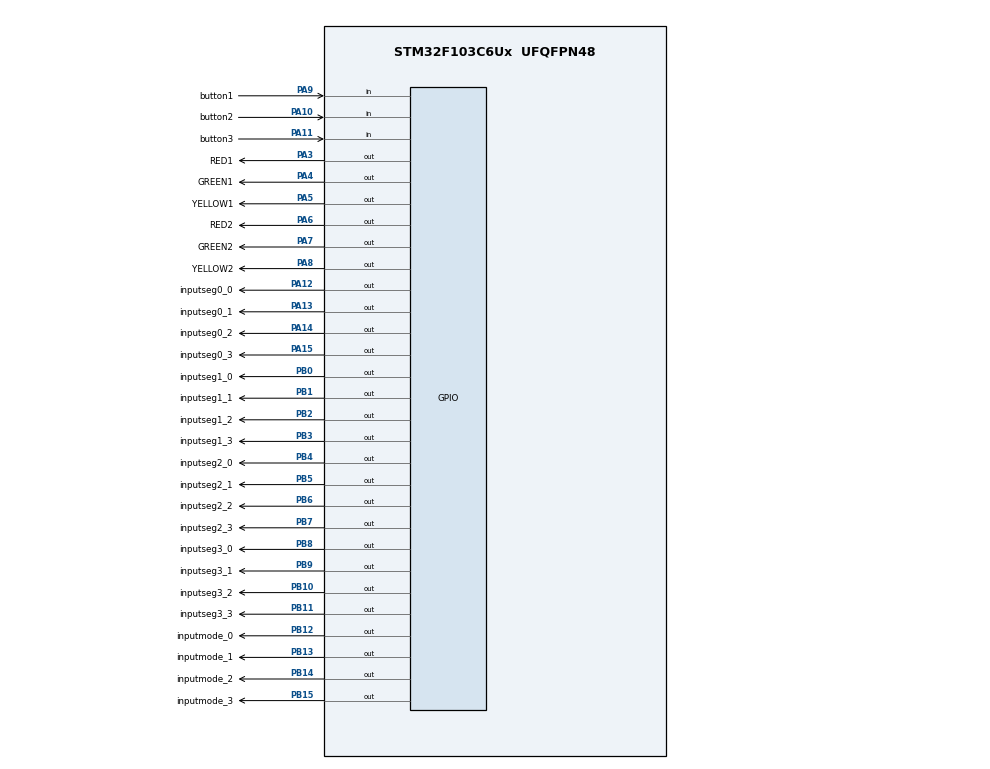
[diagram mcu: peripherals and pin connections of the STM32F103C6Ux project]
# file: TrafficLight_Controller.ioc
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Mcu.Family=STM32F1
Mcu.Name=STM32F103C6Ux
Mcu.Package=UFQFPN48
NVIC.PriorityGroup=NVIC_PRIORITYGROUP_4
NVIC.TIM2_IRQn=true\:0\:0\:false\:false\:true\:true\:true
PA10.GPIO_Label=button2
PA10.GPIO_PuPd=GPIO_PULLUP
PA10.Signal=GPIO_Input
PA11.GPIO_Label=button3
PA11.GPIO_PuPd=GPIO_PULLUP
PA11.Signal=GPIO_Input
PA12.GPIO_Label=inputseg0_0
PA12.GPIO_ModeDefaultOutputPP=GPIO_MODE_OUTPUT_PP
PA12.GPIO_PuPd=GPIO_NOPULL
PA12.Signal=GPIO_Output
PA13.GPIO_Label=inputseg0_1
PA13.GPIO_ModeDefaultOutputPP=GPIO_MODE_OUTPUT_PP
PA13.GPIO_PuPd=GPIO_NOPULL
PA13.Signal=GPIO_Output
PA14.GPIO_Label=inputseg0_2
PA14.Signal=GPIO_Output
PA15.GPIO_Label=inputseg0_3
PA15.Signal=GPIO_Output
PA3.GPIO_Label=RED1
PA3.Signal=GPIO_Output
PA4.GPIO_Label=GREEN1
PA4.Signal=GPIO_Output
PA5.GPIO_Label=YELLOW1
PA5.Signal=GPIO_Output
PA6.GPIO_Label=RED2
PA6.Signal=GPIO_Output
PA7.GPIO_Label=GREEN2
PA7.Signal=GPIO_Output
PA8.GPIO_Label=YELLOW2
PA8.GPIO_PuPd=GPIO_NOPULL
PA8.Signal=GPIO_Output
PA9.GPIO_Label=button1
PA9.GPIO_PuPd=GPIO_PULLUP
PA9.Signal=GPIO_Input
PB0.GPIO_Label=inputseg1_0
PB0.Signal=GPIO_Output
PB1.GPIO_Label=inputseg1_1
PB1.Signal=GPIO_Output
PB10.GPIO_Label=inputseg3_2
PB10.Signal=GPIO_Output
PB11.GPIO_Label=inputseg3_3
PB11.Signal=GPIO_Output
PB12.GPIO_Label=inputmode_0
PB12.Signal=GPIO_Output
PB13.GPIO_Label=inputmode_1
PB13.Signal=GPIO_Output
PB14.GPIO_Label=inputmode_2
PB14.Signal=GPIO_Output
PB15.GPIO_Label=inputmode_3
PB15.Signal=GPIO_Output
PB2.GPIO_Label=inputseg1_2
PB2.Signal=GPIO_Output
PB3.GPIO_Label=inputseg1_3
PB3.Signal=GPIO_Output
PB4.GPIO_Label=inputseg2_0
PB4.Signal=GPIO_Output
PB5.GPIO_Label=inputseg2_1
PB5.Signal=GPIO_Output
PB6.GPIO_Label=inputseg2_2
PB6.Signal=GPIO_Output
PB7.GPIO_Label=inputseg2_3
PB7.Signal=GPIO_Output
PB8.GPIO_Label=inputseg3_0
PB8.Signal=GPIO_Output
PB9.GPIO_Label=inputseg3_1
PB9.Signal=GPIO_Output
ProjectManager.HeapSize=0x200
ProjectManager.StackSize=0x400
ProjectManager.TargetToolchain=STM32CubeIDE
RCC.APB1Freq_Value=8000000
RCC.APB2Freq_Value=8000000
TIM2.Period=9
TIM2.Prescaler=7999
VP_SYS_VS_ND.Mode=No_Debug
VP_TIM2_VS_ClockSourceINT.Mode=Internal
board=custom

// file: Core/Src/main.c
/* USER CODE BEGIN Header */
/**
  ******************************************************************************
  * @file           : main.c
  * @brief          : Traffic Light System - Main Program (FIXED)
  *                   Chương trình chính đi�?u khiển hệ thống đèn giao thông
  ******************************************************************************
  */
/* USER CODE END Header */
#include "main.h"

/* USER CODE BEGIN Includes */
#include "software_timer.h"    // Thư viện timer phần m�?m (đếm th�?i gian)
#include "button.h"            // Thư viện xử lý nút nhấn
#include "fsm_traffic.h"       // Thư viện FSM (Finite State Machine) đi�?u khiển đèn giao thông
/* USER CODE END Includes */

/* USER CODE BEGIN Header */
/**
  ******************************************************************************
  * @file           : main.c
  * @brief          : Traffic Light System - Main Program (FIXED)
  *                   Chương trình chính điều khiển hệ thống đèn giao thông
  ******************************************************************************
  */
/* USER CODE END Header */

#include "main.h"

/* USER CODE BEGIN Includes */
#include "software_timer.h"    // Thư viện timer phần mềm (đếm thời gian)
#include "button.h"            // Thư viện xử lý nút nhấn
#include "fsm_traffic.h"       // Thư viện FSM (Finite State Machine) điều khiển đèn giao thông
/* USER CODE END Includes */

TIM_HandleTypeDef htim2;    // Biến quản lý Timer 2 (phần cứng)

void SystemClock_Config(void);       // Hàm cấu hình xung clock hệ thống
static void MX_GPIO_Init(void);      // Hàm khởi tạo GPIO (các chân input/output)
static void MX_TIM2_Init(void);      // Hàm khởi tạo Timer 2

/**
  * @brief  Timer interrupt callback - Hàm ngắt Timer
  * @param  htim: Timer handle (con trỏ tới timer đang xử lý)
  * @retval None
  *
  * Giải thích:
  * - Hàm này được gọi TỰ ĐỘNG mỗi khi Timer 2 tràn (overflow)
  * - Thời gian gọi phụ thuộc vào cấu hình Timer (thường là 10ms)
  * - Đây là "tim đập" của hệ thống - mọi xử lý theo thời gian đều dựa vào đây
  */
void HAL_TIM_PeriodElapsedCallback(TIM_HandleTypeDef *htim)
{
    // Kiểm tra xem ngắt có phải từ Timer 2 không
    if (htim->Instance == TIM2) {

        // 1. Cập nhật bộ đếm timer phần mềm
        //    - Giảm giá trị các timer đã set
        //    - Kiểm tra timer nào hết thời gian
        timerRun();

        // 2. Đọc trạng thái các nút nhấn
        //    - Quét trạng thái nút (nhấn/thả)
        //    - Xử lý chống dội phím (debounce)
        //    - Phát hiện sự kiện nhấn (pressed/long pressed)
        getKeyInput();

        // 3. Chạy máy trạng thái điều khiển đèn giao thông
        //    - Xử lý logic chuyển đèn đỏ-vàng-xanh
        //    - Cập nhật LED 7 đoạn
        //    - Xử lý các mode (normal, adjust red, adjust yellow, adjust green)
        traffic_run();
    }
}

int main(void)
{

  /* MCU Configuration--------------------------------------------------------*/

  /* Reset of all peripherals, Initializes the Flash interface and the Systick. */
  HAL_Init();

  /* Configure the system clock */
  SystemClock_Config();

  /* Initialize all configured peripherals */
  MX_GPIO_Init();
  MX_TIM2_Init();
  /* USER CODE BEGIN 2 */

  // Khởi tạo hệ thống đèn giao thông
  traffic_init();
  // Bật Timer interrupt
  HAL_TIM_Base_Start_IT(&htim2);

  /* USER CODE END 2 */

  /* Infinite loop */
  while (1)
  {

  }
}

void SystemClock_Config(void)
{
  RCC_OscInitTypeDef RCC_OscInitStruct = {0};
  RCC_ClkInitTypeDef RCC_ClkInitStruct = {0};

  /** Initializes the RCC Oscillators according to the specified parameters
  * in the RCC_OscInitTypeDef structure.
  */
  RCC_OscInitStruct.OscillatorType = RCC_OSCILLATORTYPE_HSI;
  RCC_OscInitStruct.HSIState = RCC_HSI_ON;
  RCC_OscInitStruct.HSICalibrationValue = RCC_HSICALIBRATION_DEFAULT;
  RCC_OscInitStruct.PLL.PLLState = RCC_PLL_NONE;
  if (HAL_RCC_OscConfig(&RCC_OscInitStruct) != HAL_OK)
  {
    Error_Handler();
  }
  /** Initializes the CPU, AHB and APB buses clocks
  */
  RCC_ClkInitStruct.ClockType = RCC_CLOCKTYPE_HCLK|RCC_CLOCKTYPE_SYSCLK
                              |RCC_CLOCKTYPE_PCLK1|RCC_CLOCKTYPE_PCLK2;
  RCC_ClkInitStruct.SYSCLKSource = RCC_SYSCLKSOURCE_HSI;
  RCC_ClkInitStruct.AHBCLKDivider = RCC_SYSCLK_DIV1;
  RCC_ClkInitStruct.APB1CLKDivider = RCC_HCLK_DIV1;
  RCC_ClkInitStruct.APB2CLKDivider = RCC_HCLK_DIV1;

  if (HAL_RCC_ClockConfig(&RCC_ClkInitStruct, FLASH_LATENCY_0) != HAL_OK)
  {
    Error_Handler();
  }
}

static void MX_TIM2_Init(void)
{

  TIM_ClockConfigTypeDef sClockSourceConfig = {0};
  TIM_MasterConfigTypeDef sMasterConfig = {0};

  htim2.Instance = TIM2;
  htim2.Init.Prescaler = 7999;
  htim2.Init.CounterMode = TIM_COUNTERMODE_UP;
  htim2.Init.Period = 9;
  htim2.Init.ClockDivision = TIM_CLOCKDIVISION_DIV1;
  htim2.Init.AutoReloadPreload = TIM_AUTORELOAD_PRELOAD_DISABLE;
  if (HAL_TIM_Base_Init(&htim2) != HAL_OK)
  {
    Error_Handler();
  }
  sClockSourceConfig.ClockSource = TIM_CLOCKSOURCE_INTERNAL;
  if (HAL_TIM_ConfigClockSource(&htim2, &sClockSourceConfig) != HAL_OK)
  {
    Error_Handler();
  }
  sMasterConfig.MasterOutputTrigger = TIM_TRGO_RESET;
  sMasterConfig.MasterSlaveMode = TIM_MASTERSLAVEMODE_DISABLE;
  if (HAL_TIMEx_MasterConfigSynchronization(&htim2, &sMasterConfig) != HAL_OK)
  {
    Error_Handler();
  }

}

static void MX_GPIO_Init(void)
{
  GPIO_InitTypeDef GPIO_InitStruct = {0};

  /* GPIO Ports Clock Enable */
  __HAL_RCC_GPIOA_CLK_ENABLE();
  __HAL_RCC_GPIOB_CLK_ENABLE();

  /*Configure GPIO pin Output Level */
  HAL_GPIO_WritePin(GPIOA, RED1_Pin|GREEN1_Pin|YELLOW1_Pin|RED2_Pin
                          |GREEN2_Pin|YELLOW2_Pin|inputseg0_0_Pin|inputseg0_1_Pin
                          |inputseg0_2_Pin|inputseg0_3_Pin, GPIO_PIN_RESET);

  /*Configure GPIO pin Output Level */
  HAL_GPIO_WritePin(GPIOB, inputseg1_0_Pin|inputseg1_1_Pin|inputseg1_2_Pin|inputseg3_2_Pin
                          |inputseg3_3_Pin|inputmode_0_Pin|inputmode_1_Pin|inputmode_2_Pin
                          |inputmode_3_Pin|inputseg1_3_Pin|inputseg2_0_Pin|inputseg2_1_Pin
                          |inputseg2_2_Pin|inputseg2_3_Pin|inputseg3_0_Pin|inputseg3_1_Pin, GPIO_PIN_RESET);

  /*Configure GPIO pins : RED1_Pin GREEN1_Pin YELLOW1_Pin RED2_Pin
                           GREEN2_Pin YELLOW2_Pin inputseg0_0_Pin inputseg0_1_Pin
                           inputseg0_2_Pin inputseg0_3_Pin */
  GPIO_InitStruct.Pin = RED1_Pin|GREEN1_Pin|YELLOW1_Pin|RED2_Pin
                          |GREEN2_Pin|YELLOW2_Pin|inputseg0_0_Pin|inputseg0_1_Pin
                          |inputseg0_2_Pin|inputseg0_3_Pin;
  GPIO_InitStruct.Mode = GPIO_MODE_OUTPUT_PP;
  GPIO_InitStruct.Pull = GPIO_NOPULL;
  GPIO_InitStruct.Speed = GPIO_SPEED_FREQ_LOW;
  HAL_GPIO_Init(GPIOA, &GPIO_InitStruct);

  /*Configure GPIO pins : inputseg1_0_Pin inputseg1_1_Pin inputseg1_2_Pin inputseg3_2_Pin
                           inputseg3_3_Pin inputmode_0_Pin inputmode_1_Pin inputmode_2_Pin
                           inputmode_3_Pin inputseg1_3_Pin inputseg2_0_Pin inputseg2_1_Pin
                           inputseg2_2_Pin inputseg2_3_Pin inputseg3_0_Pin inputseg3_1_Pin */
  GPIO_InitStruct.Pin = inputseg1_0_Pin|inputseg1_1_Pin|inputseg1_2_Pin|inputseg3_2_Pin
                          |inputseg3_3_Pin|inputmode_0_Pin|inputmode_1_Pin|inputmode_2_Pin
                          |inputmode_3_Pin|inputseg1_3_Pin|inputseg2_0_Pin|inputseg2_1_Pin
                          |inputseg2_2_Pin|inputseg2_3_Pin|inputseg3_0_Pin|inputseg3_1_Pin;
  GPIO_InitStruct.Mode = GPIO_MODE_OUTPUT_PP;
  GPIO_InitStruct.Pull = GPIO_NOPULL;
  GPIO_InitStruct.Speed = GPIO_SPEED_FREQ_LOW;
  HAL_GPIO_Init(GPIOB, &GPIO_InitStruct);

  /*Configure GPIO pins : button1_Pin button2_Pin button3_Pin */
  GPIO_InitStruct.Pin = button1_Pin|button2_Pin|button3_Pin;
  GPIO_InitStruct.Mode = GPIO_MODE_INPUT;
  GPIO_InitStruct.Pull = GPIO_PULLUP;
  HAL_GPIO_Init(GPIOA, &GPIO_InitStruct);

}

void Error_Handler(void)
{
  __disable_irq();
  while (1)
  {
  }
}

/************************ (C) COPYRIGHT STMicroelectronics *****END OF FILE****/
